# EHCI register map
Vendor: Texas Instruments
Peripheral module from a debugger description file (folder omap36xx).
Registers are 32-bit, access per field, reset values left out (the file's numbers can be read two ways) unless marked. A register's access mark holds for its fields unless they carry their own. Offsets are as the file gives them; lines under a group give offsets from that group; [hi:lo] are bit positions; {n}, {i} and the like mark numbered series; 'fields as' and 'values as' point back to an identical list; <NAME> marks a mode.

## EHCI
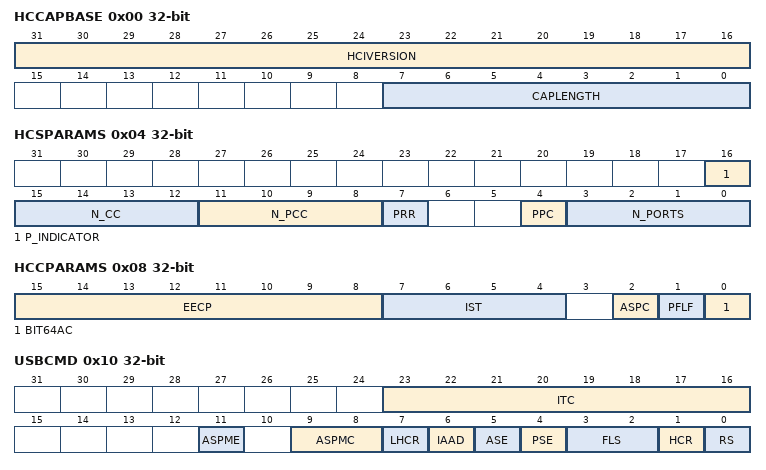
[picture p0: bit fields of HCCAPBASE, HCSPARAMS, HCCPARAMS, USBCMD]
0x00 HCCAPBASE ro — Host Controller Capability register
  [31:16] HCIVERSION — Interface version number It contains a BCD encoding of the EHCI revision number supported by this host controller.[7:4] Major revision . [3:0] Minor revision .
  [7:0] CAPLENGTH — Capability register length
0x04 HCSPARAMS ro — Host Controller Structural Parameters
  [16] P_INDICATOR — Port indicator support indicationThis bit indicates whether the ports support port indicator control. .
    1=The port status and control registers include a read/write field for controlling the state of the port indicator
  [15:12] N_CC — Number of Companion ControllersThis field indicates the number of companion controllers associated with this USB 2.0 host controller. . Others: there are companion USB 1.1 host controller(s). Port-ownership hand-off is supported. High-, full-, and low-speed devices are supported on the host controller root ports. .
    0=There are no companion host controllers. Port-ownership hand-off is not supported. Only high-speed devices are supported on the host controller root ports.
  [11:8] N_PCC — Number of Ports per Companion ControllerThis field indicates the number of ports supported per companion host controller. It is used to indicate the port routing configuration to system software. . For example, if N_PORTS has a value of 6 and N_CC has a value of 2, then N_PCC can have a value of 3. . The convention is that the first N_PCC ports are assumed to be routed to companion controller 1, the next N_PCC ports to companion controller 2, etc. . The number in this field must be consistent with N_PORTS and N_CC. .
  [7] PRR — Port Routing RulesThe first N_PCC ports are routed to the lowest-numbered function companion host controller, the next N_PCC ports are routed to the next lowest-function companion controller, and so on. .
  [4] PPC — Port Power controlThis field indicates whether the host controller implementation includes port power control. .
    0=The ports do not have port power switches; 1=The ports have port power switches
  [3:0] N_PORTS — Number of downstream portsThis field specifies the number of physical downstream ports implemented on this host controller. .
0x08 HCCPARAMS ro — Host Controller Capability Parameters
  [15:8] EECP — EHCI Extended Capabilities PointerThis field indicates the existence of a capabilities list. . Others: The offset in PCI configuration space of the first EHCI extended capability. .
    0=No extended capabilities are implemented
  [7:4] IST — Isochronous Scheduling ThresholdThis field indicateswhere software can reliably update the isochronous schedule in relation to the current position of the executing host controller. . The host controller can hold 1 microframe of isochronous data structures before flushing the state. .
  [2] ASPC — Asynchronous Schedule Park CapabilityThe feature can be disabled or enabled and set to a specific level by using the USBHOST.[11]ASPME and the USBHOST.[9:8] ASPMC fields. .
    1=The host controller supports the park feature for high-speed queue heads in the asynchronous schedule
  [1] PFLF — Programmable Frame List Flag
    0=System software must use a frame list length of 1024 elements with this host controller; 1=System software can specify and use a smaller frame list and configure the host controller via the USBHOST.[3:2] FLS field. The frame list must always be aligned on a 4K-page boundary.
  [0] BIT64AC — 64-bit addressing capabilityThis field documents the addressing range capability of this implementation. .
    0=Data structures using 32-bit address memory pointers; 1=Data structures using 64-bit address memory pointers
0x10 USBCMD — USB Command
  [23:16] ITC rw — Interrupt Threshold ControlThis field is used by the system software to select the maximum rate at which the host controller issues interrupts. The only valid values are defined below. If software writes an invalid value to this register, the results are undefined. . Others: Undefined .
    1=1 microframe; 2=2 microframes; 4=4 microframes; 8=8 microframes (default, equates to 1 ms); 16=16 microframes (2 ms); 32=32 microframes (4 ms); 64=64 microframes (8 ms)
  [11] ASPME rw — Asynchronous Schedule Park Mode Enable
    0=Park mode is disabled; 1=Park mode is enabled
  [9:8] ASPMC rw — Asynchronous Schedule Park Mode CountIt contains a count of the number of successive transactions the host controller is allowed to execute from a high-speed queue head on the asynchronous schedule before continuing traversal of the asynchronous schedule. . Valid values are 0x1 to 0x3. The software must not write a 0 to this bit when Park Mode Enable is a 1 as this may result in undefined behavior. .
  [7] LHCR rw — Light Host Controller ResetIt allows the driver to reset the EHCI controller without affecting the state of the ports or the relationship to the companion host controllers. .
    0=LHCR_0_r (Light host controller reset is complete and it is safe for host software to reinitialize the host controller.); 1=LHCR_1_r (Light host controller reset is still ongoing.)
  [6] IAAD rw — Interrupt on Async Advance DoorbellThis bit is used as a doorbell by software to tell the host controller to issue an interrupt the next time it advances asynchronous schedule. . Software should not write a 1 to this bit when the asynchronous schedule is disabled. Doing so may yield undefined results. .
    1=IAAD_1_w (Ring the doorbell.)
  [5] ASE rw — Asynchronous Schedule EnableThis bit controls whether the host controller skips processing the asynchronous schedule. .
    0=Do not process the asynchronous schedule; 1=Use the USBHOST. register to access the asynchronous schedule.
  [4] PSE rw — Periodic Schedule EnableThis bit controls whether the host controller skips processing the periodic schedule. .
    0=Do not process the periodic schedule; 1=Use the USBHOST. register to access the periodic schedule.
  [3:2] FLS rw — Frame List SizeThis field specifies the size of the frame list. The size of the frame list controls which bits in the frame index register should be used for the frame list vurrent index. .
    0=1024 elements (4096 bytes); 1=512 elements (2048 bytes); 2=256 elements (1024 bytes), for resource-constrained environments
  [1] HCR wo — Host Controller ResetThis control bit is used by software to reset the host controller. Write . This bit is set to 0 by the host controller when the reset process is complete. .
    1=Reset the host controller, the PCI configuration registers are not affected by this reset and all operational registers are set to their initial values
  [0] RS rw — Run/stop
    1=Run, the host controller proceeds with execution of the schedule. The host controller continues execution as long as this bit is set to 1.; 0=Stop, the host controller completes the current and any actively pipelined transactions on the USB and then halts
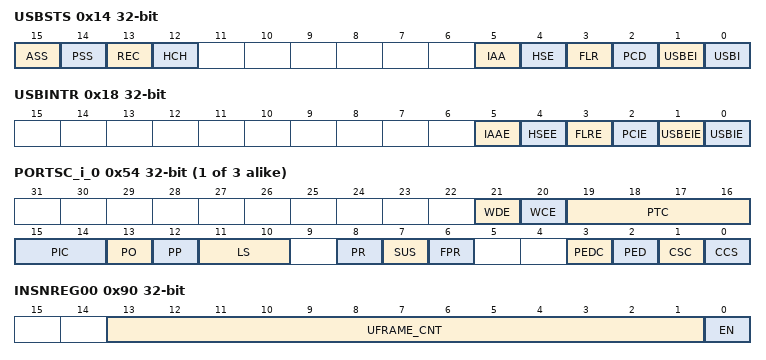
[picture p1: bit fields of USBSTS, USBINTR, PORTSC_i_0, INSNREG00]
0x14 USBSTS — USB status
  [15] ASS ro — Asynchronous Schedule StatusThe bit reports the current real status of the asynchronous schedule. .
    0=The status of the asynchronous schedule is disabled; 1=The status of the asynchronous schedule is enabled
  [14] PSS ro — Periodic Schedule StatusThe bit reports the current real status of the periodic schedule. .
    0=The status of the periodic schedule is disabled; 1=The status of the periodic schedule is enabled
  [13] REC ro — ReclamationIt is used to detect an empty asynchronous schedule. .
  [12] HCH ro — Host Controller HaltedThis bit is a 0 whenever the USBHOST.[0] . RS bit is a 1. The host controller sets this bit to 1 after it has stopped executing as a result of the RS bit being set to 0, either by software or by the host controller hardware. .
  [5] IAA rw — Interrupt on Async AdvanceSystem software can force the host controller to issue an interrupt the next time the host controller advances the asynchronous schedule by writing a 1 in the USBHOST.[6] IAAD bit. This status bit indicates the assertion of that interrupt source. .
  [4] HSE rw — Host System ErrorThe host controller sets this bit to 1 when a serious error occurs during a host system access involving the host controller module. .
  [3] FLR rw — Frame List RolloverThe host controller sets this bit to 1 when the USBHOST. rolls over from its maximum value to 0. The exact value at which the rollover occurs depends on the frame list size. .
  [2] PCD rw — Port Change DetectThe host controller sets this bit to 1 when any port for which the USBHOST.[13] PO bit is set to 0 has a change bit transition from a 0 to a 1 or a USBHOST.[6] FPR bit transition from a 0 to a 1. . This bit is also set as a result of the USBHOST.[1] CSC bit being set to 1 after system software has relinquished ownership of a connected port by writing a 1 to a USBHOST.[13] PO bit. .
  [1] USBEI rw — USB Error InterruptThe host controller sets this bit to 1 when completion of a USB transaction results in an error condition. .
  [0] USBI rw — USB InterruptThe host controller sets this bit to 1 on completion of a USB transaction, which results in the retirement of a transfer descriptor that had its IOC bit set. . The host controller also sets this bit to 1 when a short packet is detected (actual number of bytes received was less than the expected number of bytes). .
0x18 USBINTR — USB interrupt enable
  [5] IAAE rw — Interrupt on Async Advance Enable
    1=When the USBHOST.[5] IAA bit is 1, the host controller issues an interrupt at the next interrupt threshold. The interrupt is acknowledged by software clearing the USBHOST.[5] IAA bit.
  [4] HSEE rw — Host System Error Enable
    1=When the USBHOST.[4] HSE bit is 1, the host controller issues an interrupt. The interrupt is acknowledged by software clearing the USBHOST.[4] HSE bit.
  [3] FLRE rw — Frame List Rollover Enable
    1=When the USBHOST.[3] FLR bit is 1, the host controller issues an interrupt. The interrupt is acknowledged by software clearing the USBHOST.[3] FLR bit.
  [2] PCIE rw — Port Change Interrupt Enable
    1=When the USBHOST.[2] PCD bit is 1, the host controller issues an interrupt. The interrupt is acknowledged by software clearing the USBHOST.[3] FLR bit.
  [1] USBEIE rw — USB Error Interrupt Enable
    1=When the USBHOST.[1] USBEI bit is 1, the host controller issues an interrupt at the next interrupt threshold. The interrupt is acknowledged by software clearing the USBHOST.[1] USBEI bit.
  [0] USBIE rw — USB Interrupt Enable
    1=When the USBHOST.[0] USBI bit is 1, the host controller issues an interrupt at the next interrupt threshold. The interrupt is acknowledged by software clearing the USBHOST.[0] USBI bit.
0x1C FRINDEX — USB frame index
  [13:0] FI rw — Frame indexThe value in this register is incremented at the end of each time frame. .
0x20 CTRLDSSEGMENT ro — 4G segment selector
  [31:0] CDSS — This 32-bit register corresponds to the most significant address bits [63:32] for all EHCI data structures.
0x24 PERIODICLISTBASE — Frame list base address
  [31:12] BAL rw — Base address (low)These bits correspond to memory address signals. .
0x28 ASYNCLISTADDR — Next asynchronous list address
  [31:5] LPL rw — Link Pointer LowIt contains the address of the next asynchronous queue head to be executed. .
0x50 CONFIGFLAG — Configured flag register
  [0] CF rw — Configure FlagThis bit controls the default port-routing control logic. .
    0=Port routing control logic default-routes each port to an implementation dependent classic host controller; 1=Port routing control logic default-routes all ports to this host controller
{0x54+4i} PORTSC_i_{i} (i=0..2) — Port Status/Control
  [21] WDE rw — Wake on Disconnect EnableThis field is 0 if the PP bit is 0. .
    1=WDE_1_w (Enables the port to be sensitive to device disconnects as wake-up events.)
  [20] WCE rw — Wake on Connect EnableThis field is 0 if the PP bit is 0. .
    1=WCE_1_w (Enables the port to be sensitive to device connects as wake-up events.)
  [19:16] PTC rw — Port Test ControlThe port is operating in specific test modes as indicated by the specific value. The encoding of the test mode bits are: . Others: Reserved .
    0=Test mode not enabled; 1=Test J_STATE; 2=Test K_STATE; 3=Test SE0_NAK; 4=Test Packet; 5=Test FORCE_ENABLE
  [15:14] PIC ro — Port Indicator Control (not implemented)
  [13] PO rw — Port OwnerThis bit unconditionally goes to a 0x0 when the USBHOST.[0] CF bit makes a 0 to 1 transition. This bit unconditionally goes to 0 whenever the USBHOST.[0] CF bit is 0. .
    1=A companion host controller owns and controls the port
  [12] PP rw — Port PowerThe function of this bit depends on the value of the USBHOST.[4] PPC bit. The behavior is as follows: . PPC PP Operation . 0x0 0x1 Host controller does not have port power. control switches. Each port is hard-wired to power. . 0x1 N/A Host controller has port power control switches. This bit represents the current setting of the switch (0 = Off, 1 = On). . When an overcurrent condition is detected on a powered port and the USBHOST.[4] PPC bit is a 1, the PP bit in each affected port may be transitioned by the host controller from 1 to 0. .
  [11:10] LS ro — Line StatusThese bits reflect the current logical levels of the D+ (bit 11) and D– (bit 10) signal lines. This field is valid only when the port enable bit is 0 and the current connect status bit is set to 1. The encoding of the bits is: . Bits[11:10] USB State Interpretation . 0x0 SE0 Not low-speed device, perform EHCI reset. . 0x2 J-state Not low-speed device, perform EHCI reset. . 0x1 K-state Low-speed device, release ownership of port. . 0x3 Undefined Not low-speed device, perform EHCI reset. .
  [8] PR rw — Port ResetThis field is 0 if the PP bit is 0. . Write 0x1 when at 0x0: The bus reset sequence is started. .
    0=Port is not in reset; 1=Port is in reset; 0=PR_0_w (Terminate the bus reset sequence.)
  [7] SUS rw — SuspendThis field is 0 if the PP bit is 0. . 0x0 when PED = 0x1: Port enabled . 0x1 when PED = 0x1: Port in suspend state .
    0=Port disabled
  [6] FPR rw — Force Port ResumeThis field is 0 if the PP bit is 0. .
    0=No resume (K-state) detected/driven on port; 1=Resume detected/driven on port
  [3] PEDC rw — Port Enabled/Disabled ChangeThis field is 0 if the PP bit is 0. .
    0=PEDC_0_r (No change.); 1=PEDC_1_r (Port enabled/disabled status has changed.); 1=PEDC_1_w (Clears this bit to 0.)
  [2] PED rw — Port Enabled/DisabledSoftware cannot enable a port by writing a 1 to this field. The host controller only sets this to 1 when the reset sequence determines that the attached device is a high-speed device. . Ports can be disabled by either a fault condition (disconnect event or other fault condition) or by host software. . This field is 0 if the PP bit is 0. .
    0=Disable; 1=Enable
  [1] CSC rw — Connect Status ChangeIndicates a change has occurred in the port CCS bit. . This field is 0 if the PP bit is 0. .
    0=CSC_0_r (No change); 1=CSC_1_r (Change in current connect status); 1=CSC_1_w (Clears this bit to 0)
  [0] CCS ro — Current Connect StatusThis value reflects the current state of the port, and may not correspond directly to the event that caused the CSC bit to be set. . This field is 0 if the PP bit is 0. .
    0=No device is present; 1=Device is present on port
0x90 INSNREG00 — Implementation-specific register #0
  [13:1] UFRAME_CNT rw — 1-microframe length value, to reduce simulation timeSIMULATIONS ONLY, NOT AN ACTUAL REGISTER
  [0] EN rw — Enable of this register
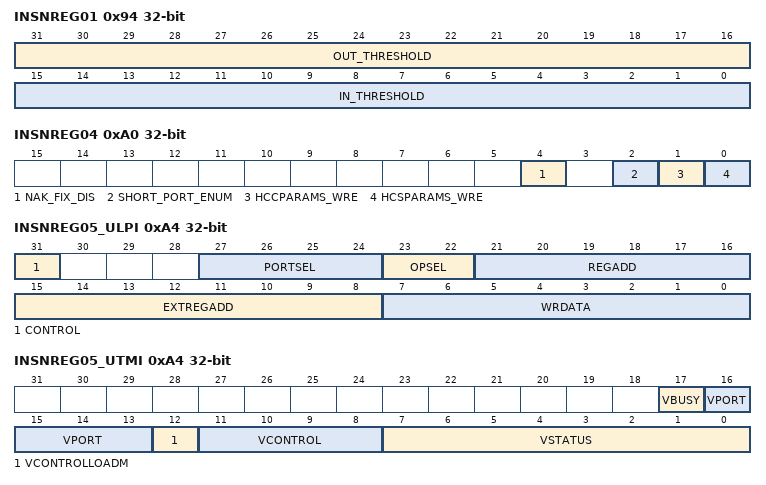
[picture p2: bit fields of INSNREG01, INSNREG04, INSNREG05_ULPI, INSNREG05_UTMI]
0x94 INSNREG01 rw — Implementation-specific register #1
  [31:16] OUT_THRESHOLD — Programmable output packet buffer threshold, in 32-bit words
  [15:0] IN_THRESHOLD — Programmable input packet buffer threshold, in 32-bit words
0x98 INSNREG02 — Implementation-specific register #2
  [11:0] BUF_DEPTH rw — Programmable packet buffer depth, in 32-bit words
0x9C INSNREG03 — Implementation-specific register #3
  [0] BRK_MEM_TRSF rw — Break Memory Transfer, withINSNREG01
    0=Disabled; 1=Enabled
0xA0 INSNREG04 — Implementation-specific register #4
  [4] NAK_FIX_DIS rw — Disable NAK fix (don't touch)
  [2] SHORT_PORT_ENUM rw — Scale down Port enumeration time (debug)
  [1] HCCPARAMS_WRE rw — Make read-onlyHCCPARAMS register writable (debug)
  [0] HCSPARAMS_WRE rw — Make read-onlyHCSPARAMS register writable (debug)
0xA4 INSNREG05_ULPI — Implementation-specific register #5 Register functionality for ULPI mode
  [31] CONTROL rw — Control/status of the ULPI register access
    0=ULPI access done; 1=Start ULPI access
  [27:24] PORTSEL rw
    1=Port 1 selected for register access; 2=Port 2 selected for register access; 3=Port 3 selected for register access
  [23:22] OPSEL rw
    2=Register access is Write; 3=Register access is Read
  [21:16] REGADD rw — ULPI direct register address, for any value different than 0x2F.
    47=Triggers an extended address
  [15:8] EXTREGADD rw — Address for extended register accesses. Don't care for direct accesses.
  [7:0] WRDATA rw — Read/Write data of register access
0xA4 INSNREG05_UTMI — Implementation-specific register #5 Register functionality for UTMI mode
  [17] VBUSY ro
    0=Vendor interface is done/inactive; 1=Vendor interface is busy
  [16:13] VPORT rw — Vendor interface port selection
    1=Port 1 vendor interface selected; 2=Port 2 vendor interface selected; 3=Port 3 vendor interface selected
  [12] VCONTROLLOADM rw — UTMI VcontrolLoadM output (active-low)
    0=Load Vcontrol value into PHY; 1=No Action
  [11:8] VCONTROL rw — UTMI Vcontrol output, to be loaded into the PHY
  [7:0] VSTATUS ro — UTMI Vstatus input image, from PHY
